AUTOSAR XML (schema 314)
package /ComponentType
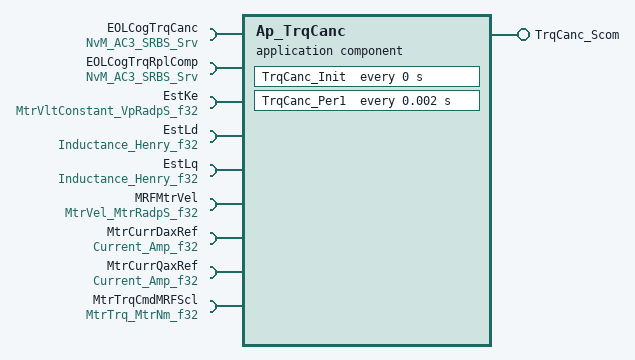
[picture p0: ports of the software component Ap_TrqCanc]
  application software component type Ap_TrqCanc  # Generates the Current Command and the Voltage Reference for the Current Control
    provide port TrqCanc_Scom: provided-interface=TrqCanc_Scom
      provided-com-specs:
        operation=ReadCogTrqCal, queue-length=1
        operation=ReadCogTrqCalComp, queue-length=1
        operation=SetCogTrqCal, queue-length=1
        operation=SetCogTrqCalComp, queue-length=1
    9 x require port:
      EOLCogTrqCanc: required-com-specs=[EraseBlock, GetErrorStatus, InvalidateNvBlock, ReadBlock, SetRamBlockStatus, WriteBlock], required-interface=NvM_AC3_SRBS_Srv
      EOLCogTrqRplComp: required-com-specs=[EraseBlock, GetErrorStatus, InvalidateNvBlock, ReadBlock, SetRamBlockStatus, WriteBlock], required-interface=NvM_AC3_SRBS_Srv
      EstKe: unqueued-receiver-com-spec{data-element=VpRadpS_f32, init-value=D_ZERO_ULS_F32}, required-interface=MtrVltConstant_VpRadpS_f32
      EstLd: unqueued-receiver-com-spec{data-element=Henry_f32, init-value=D_ZERO_ULS_F32}, required-interface=Inductance_Henry_f32
      EstLq: unqueued-receiver-com-spec{data-element=Henry_f32, init-value=D_ZERO_ULS_F32}, required-interface=Inductance_Henry_f32
      MRFMtrVel: unqueued-receiver-com-spec{data-element=MtrRadpS_f32, init-value=D_ZERO_ULS_F32}, required-interface=MtrVel_MtrRadpS_f32
      MtrCurrDaxRef: unqueued-receiver-com-spec{data-element=Amp_f32, init-value=D_ZERO_ULS_F32}, required-interface=Current_Amp_f32
      MtrCurrQaxRef: unqueued-receiver-com-spec{data-element=Amp_f32, init-value=D_ZERO_ULS_F32}, required-interface=Current_Amp_f32
      MtrTrqCmdMRFScl: unqueued-receiver-com-spec{data-element=MtrNm_f32, init-value=D_ZERO_ULS_F32}, required-interface=MtrTrq_MtrNm_f32
  internal behavior Ap_TrqCanc_InternalBehavior: component=Ap_TrqCanc
    timing event TrqCanc_InitEvent: start-on-event=TrqCanc_Init, period=0
    timing event TMT_TrqCanc_Per1: start-on-event=TrqCanc_Per1, period=0.002
    operation invoked event OIT_TrqCanc_Scom_ReadCogTrqCal_TrqCanc_Scom_ReadCogTrqCal: start-on-event=TrqCanc_Scom_ReadCogTrqCal, operation=TrqCanc_Scom.ReadCogTrqCal
    operation invoked event OIT_TrqCanc_Scom_SetCogTrqCal_TrqCanc_Scom_SetCogTrqCal: start-on-event=TrqCanc_Scom_SetCogTrqCal, operation=TrqCanc_Scom.SetCogTrqCal
    per instance memory CogTrqCal: type=CoggingCancTrq, type-definition=/DataType/CoggingCancTrq
    per instance memory CogTrqRplComp: type=CoggingCancTrqRplComp, type-definition=/DataType/CoggingCancTrqRplComp
    port-api-options:
      enable-take-address=false, indirect-api=false, port=EOLCogTrqCanc
      enable-take-address=false, indirect-api=false, port=EOLCogTrqRplComp
      enable-take-address=false, indirect-api=false, port=EstKe
      enable-take-address=false, indirect-api=false, port=EstLd
      enable-take-address=false, indirect-api=false, port=EstLq
      enable-take-address=false, indirect-api=false, port=MRFMtrVel
      enable-take-address=false, indirect-api=false, port=MtrCurrDaxRef
      enable-take-address=false, indirect-api=false, port=MtrCurrQaxRef
      enable-take-address=false, indirect-api=false, port=MtrTrqCmdMRFScl
      enable-take-address=false, indirect-api=false, port=TrqCanc_Scom
    4 x runnable:
      TrqCanc_Init
        data read access READ_EstKe_VpRadpS_f32: data-element=EstKe.VpRadpS_f32
      TrqCanc_Per1
        7 x data read access:
          READ_EstKe_VpRadpS_f32: data-element=EstKe.VpRadpS_f32
          READ_EstLd_Henry_f32: data-element=EstLd.Henry_f32
          READ_EstLq_Henry_f32: data-element=EstLq.Henry_f32
          READ_MRFMtrVel_MtrRadpS_f32: data-element=MRFMtrVel.MtrRadpS_f32
          READ_MtrCurrDaxRef_Amp_f32: data-element=MtrCurrDaxRef.Amp_f32
          READ_MtrCurrQaxRef_Amp_f32: data-element=MtrCurrQaxRef.Amp_f32
          READ_MtrTrqCmdMRFScl_MtrNm_f32: data-element=MtrTrqCmdMRFScl.MtrNm_f32
      TrqCanc_Scom_ReadCogTrqCal
      TrqCanc_Scom_SetCogTrqCal
        sync call SC_EOLCogTrqCanc_WriteBlock: operation=EOLCogTrqCanc.WriteBlock, timeout=0
        sync call SC_EOLCogTrqRplComp_WriteBlock: operation=EOLCogTrqRplComp.WriteBlock, timeout=0
    service-needss:
      swc nv block needs CogTrqRplCompBlk: n-data-sets=0, readonly=false, reliability=LOW, resistant-to-changed-sw=false, restore-at-start=false, write-only-once=false, writing-frequency=0, writing-priority=LOW, mirror-block=CogTrqRplComp
      swc nv block needs CogTrqCalBlk: n-data-sets=0, readonly=false, reliability=LOW, resistant-to-changed-sw=false, restore-at-start=false, write-only-once=false, writing-frequency=0, writing-priority=LOW, mirror-block=CogTrqCal
  swc implementation Ap_TrqCanc_Implementation: behavior=Ap_TrqCanc_InternalBehavior
    code-descriptors:
      code Code: type=SRC
